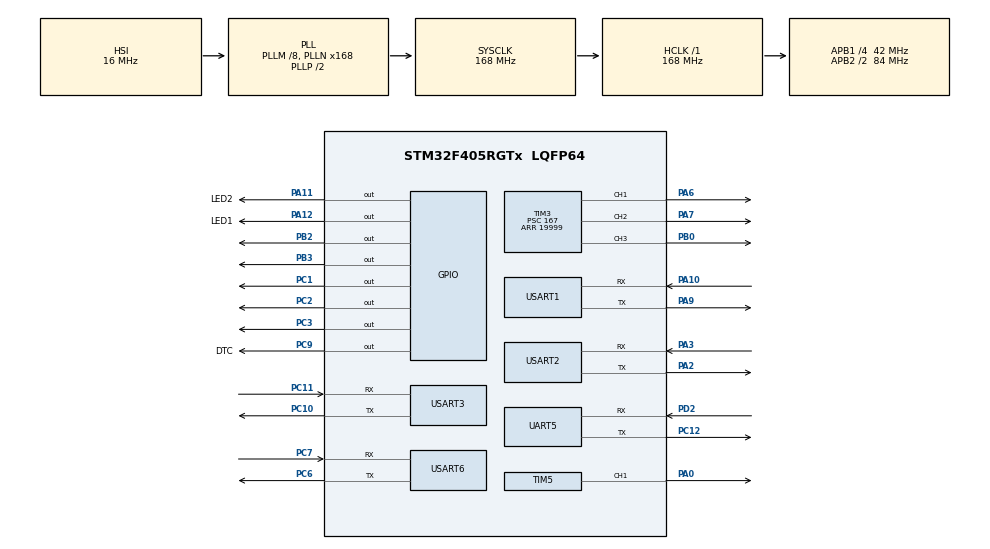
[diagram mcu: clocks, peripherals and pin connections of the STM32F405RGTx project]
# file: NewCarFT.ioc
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Dma.Request0=UART5_RX
Dma.Request1=UART5_TX
Dma.UART5_RX.0.Direction=DMA_PERIPH_TO_MEMORY
Dma.UART5_RX.0.FIFOMode=DMA_FIFOMODE_DISABLE
Dma.UART5_RX.0.Instance=DMA1_Stream0
Dma.UART5_RX.0.MemDataAlignment=DMA_MDATAALIGN_BYTE
Dma.UART5_RX.0.MemInc=DMA_MINC_ENABLE
Dma.UART5_RX.0.Mode=DMA_NORMAL
Dma.UART5_RX.0.PeriphDataAlignment=DMA_PDATAALIGN_BYTE
Dma.UART5_RX.0.PeriphInc=DMA_PINC_DISABLE
Dma.UART5_RX.0.Priority=DMA_PRIORITY_LOW
Dma.UART5_TX.1.Direction=DMA_MEMORY_TO_PERIPH
Dma.UART5_TX.1.FIFOMode=DMA_FIFOMODE_DISABLE
Dma.UART5_TX.1.Instance=DMA1_Stream7
Dma.UART5_TX.1.MemDataAlignment=DMA_MDATAALIGN_BYTE
Dma.UART5_TX.1.MemInc=DMA_MINC_ENABLE
Dma.UART5_TX.1.Mode=DMA_NORMAL
Dma.UART5_TX.1.PeriphDataAlignment=DMA_PDATAALIGN_BYTE
Dma.UART5_TX.1.PeriphInc=DMA_PINC_DISABLE
Dma.UART5_TX.1.Priority=DMA_PRIORITY_LOW
Mcu.Family=STM32F4
Mcu.Name=STM32F405RGTx
Mcu.Package=LQFP64
NVIC.DMA1_Stream0_IRQn=true\:0\:0\:false\:false\:true\:false\:true\:true
NVIC.DMA1_Stream7_IRQn=true\:0\:0\:false\:false\:true\:false\:true\:true
NVIC.PriorityGroup=NVIC_PRIORITYGROUP_4
NVIC.TIM1_UP_TIM10_IRQn=true\:0\:0\:false\:false\:true\:true\:true\:true
NVIC.UART5_IRQn=true\:0\:0\:false\:false\:true\:true\:true\:true
NVIC.USART1_IRQn=true\:0\:0\:false\:false\:true\:true\:true\:true
PA0-WKUP.Signal=S_TIM5_CH1
PA10.Mode=Asynchronous
PA10.Signal=USART1_RX
PA11.GPIO_Label=LED2
PA11.Signal=GPIO_Output
PA12.GPIO_Label=LED1
PA12.Signal=GPIO_Output
PA13.Mode=Serial_Wire
PA13.Signal=SYS_JTMS-SWDIO
PA14.Mode=Serial_Wire
PA14.Signal=SYS_JTCK-SWCLK
PA2.Mode=Asynchronous
PA2.Signal=USART2_TX
PA3.Mode=Asynchronous
PA3.Signal=USART2_RX
PA6.Signal=S_TIM3_CH1
PA7.Signal=S_TIM3_CH2
PA9.Mode=Asynchronous
PA9.Signal=USART1_TX
PB0.Signal=S_TIM3_CH3
PB2.Signal=GPIO_Output
PB3.Signal=GPIO_Output
PC1.Signal=GPIO_Output
PC10.Mode=Asynchronous
PC10.Signal=USART3_TX
PC11.Mode=Asynchronous
PC11.Signal=USART3_RX
PC12.Mode=Asynchronous
PC12.Signal=UART5_TX
PC2.Signal=GPIO_Output
PC3.Signal=GPIO_Output
PC6.Mode=Asynchronous
PC6.Signal=USART6_TX
PC7.Mode=Asynchronous
PC7.Signal=USART6_RX
PC9.GPIO_Label=DTC
PC9.Signal=GPIO_Output
PD2.Mode=Asynchronous
PD2.Signal=UART5_RX
ProjectManager.HeapSize=0x200
ProjectManager.StackSize=0x400
ProjectManager.TargetToolchain=MDK-ARM V5.32
RCC.48MHZClocksFreq_Value=84000000
RCC.AHBFreq_Value=168000000
RCC.APB1CLKDivider=RCC_HCLK_DIV4
RCC.APB1Freq_Value=42000000
RCC.APB1TimFreq_Value=84000000
RCC.APB2CLKDivider=RCC_HCLK_DIV2
RCC.APB2Freq_Value=84000000
RCC.APB2TimFreq_Value=168000000
RCC.CortexFreq_Value=168000000
RCC.HCLKFreq_Value=168000000
RCC.HSE_VALUE=25000000
RCC.HSI_VALUE=16000000
RCC.LSE_VALUE=32768
RCC.PLLM=8
RCC.PLLN=168
RCC.SYSCLKFreq_VALUE=168000000
RCC.SYSCLKSource=RCC_SYSCLKSOURCE_PLLCLK
RCC.VCOOutputFreq_Value=336000000
SH.S_TIM3_CH1.0=TIM3_CH1,PWM Generation1 CH1
SH.S_TIM3_CH2.0=TIM3_CH2,PWM Generation2 CH2
SH.S_TIM3_CH3.0=TIM3_CH3,PWM Generation3 CH3
SH.S_TIM5_CH1.0=TIM5_CH1,PWM Generation1 CH1
TIM1.AutoReloadPreload=TIM_AUTORELOAD_PRELOAD_ENABLE
TIM1.Period=15999
TIM1.Prescaler=999
TIM1.TIM_MasterOutputTrigger=TIM_TRGO_RESET
TIM3.AutoReloadPreload=TIM_AUTORELOAD_PRELOAD_ENABLE
TIM3.Channel-PWM\ Generation1\ CH1=TIM_CHANNEL_1
TIM3.Channel-PWM\ Generation2\ CH2=TIM_CHANNEL_2
TIM3.Channel-PWM\ Generation3\ CH3=TIM_CHANNEL_3
TIM3.Period=19999
TIM3.Prescaler=167
TIM5.AutoReloadPreload=TIM_AUTORELOAD_PRELOAD_ENABLE
TIM5.Channel-PWM\ Generation1\ CH1=TIM_CHANNEL_1
TIM5.Period=15999
TIM5.Prescaler=9
UART5.VirtualMode=Asynchronous
USART1.VirtualMode=VM_ASYNC
USART2.VirtualMode=VM_ASYNC
USART3.VirtualMode=VM_ASYNC
USART6.VirtualMode=VM_ASYNC
VP_TIM1_VS_ClockSourceINT.Mode=Internal
board=custom

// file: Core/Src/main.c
/* USER CODE BEGIN Header */
/**
  ******************************************************************************
  * @file           : main.c
  * @brief          : Main program body
  ******************************************************************************
  * @attention
  *
  * Copyright (c) 2025 STMicroelectronics.
  * All rights reserved.
  *
  * This software is licensed under terms that can be found in the LICENSE file
  * in the root directory of this software component.
  * If no LICENSE file comes with this software, it is provided AS-IS.
  *
  ******************************************************************************
  */
/* USER CODE END Header */
#include "main.h"
#include "dma.h"
#include "tim.h"
#include "usart.h"
#include "gpio.h"

void SystemClock_Config(void);

int main(void)
{

  /* MCU Configuration--------------------------------------------------------*/

  /* Reset of all peripherals, Initializes the Flash interface and the Systick. */
  HAL_Init();

  /* Configure the system clock */
  SystemClock_Config();

  /* Initialize all configured peripherals */
  MX_GPIO_Init();
  MX_DMA_Init();
  MX_USART1_UART_Init();
  MX_USART2_UART_Init();
  MX_USART3_UART_Init();
  MX_USART6_UART_Init();
  MX_UART5_Init();
  MX_TIM3_Init();
  MX_TIM5_Init();
  MX_TIM1_Init();
  /* USER CODE BEGIN 2 */
  HAL_GPIO_WritePin(GPIOA, GPIO_PIN_11, GPIO_PIN_SET);
  //HAL_GPIO_WritePin(GPIOA, GPIO_PIN_12, GPIO_PIN_SET);
  void Main(void);
  Main();
  /* USER CODE END 2 */

  /* Infinite loop */
  while (1)
  {

  }
}

void SystemClock_Config(void)
{
  RCC_OscInitTypeDef RCC_OscInitStruct = {0};
  RCC_ClkInitTypeDef RCC_ClkInitStruct = {0};

  /** Configure the main internal regulator output voltage
  */
  __HAL_RCC_PWR_CLK_ENABLE();
  __HAL_PWR_VOLTAGESCALING_CONFIG(PWR_REGULATOR_VOLTAGE_SCALE1);

  /** Initializes the RCC Oscillators according to the specified parameters
  * in the RCC_OscInitTypeDef structure.
  */
  RCC_OscInitStruct.OscillatorType = RCC_OSCILLATORTYPE_HSI;
  RCC_OscInitStruct.HSIState = RCC_HSI_ON;
  RCC_OscInitStruct.HSICalibrationValue = RCC_HSICALIBRATION_DEFAULT;
  RCC_OscInitStruct.PLL.PLLState = RCC_PLL_ON;
  RCC_OscInitStruct.PLL.PLLSource = RCC_PLLSOURCE_HSI;
  RCC_OscInitStruct.PLL.PLLM = 8;
  RCC_OscInitStruct.PLL.PLLN = 168;
  RCC_OscInitStruct.PLL.PLLP = RCC_PLLP_DIV2;
  RCC_OscInitStruct.PLL.PLLQ = 4;
  if (HAL_RCC_OscConfig(&RCC_OscInitStruct) != HAL_OK)
  {
    Error_Handler();
  }

  /** Initializes the CPU, AHB and APB buses clocks
  */
  RCC_ClkInitStruct.ClockType = RCC_CLOCKTYPE_HCLK|RCC_CLOCKTYPE_SYSCLK
                              |RCC_CLOCKTYPE_PCLK1|RCC_CLOCKTYPE_PCLK2;
  RCC_ClkInitStruct.SYSCLKSource = RCC_SYSCLKSOURCE_PLLCLK;
  RCC_ClkInitStruct.AHBCLKDivider = RCC_SYSCLK_DIV1;
  RCC_ClkInitStruct.APB1CLKDivider = RCC_HCLK_DIV4;
  RCC_ClkInitStruct.APB2CLKDivider = RCC_HCLK_DIV2;

  if (HAL_RCC_ClockConfig(&RCC_ClkInitStruct, FLASH_LATENCY_5) != HAL_OK)
  {
    Error_Handler();
  }
}

void Error_Handler(void)
{
  __disable_irq();
  while (1)
  {
  }
}
